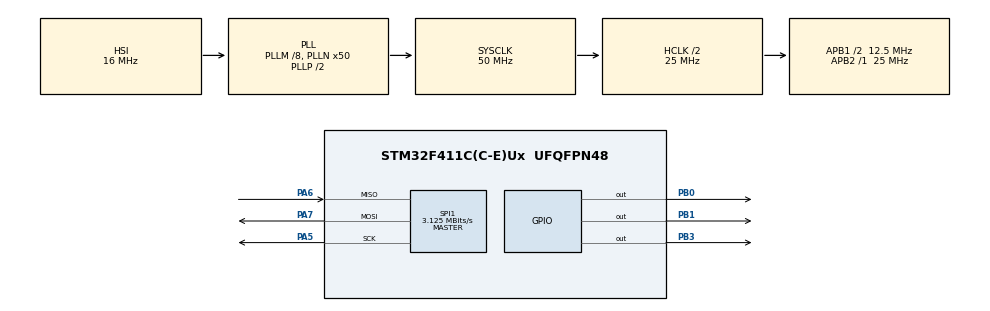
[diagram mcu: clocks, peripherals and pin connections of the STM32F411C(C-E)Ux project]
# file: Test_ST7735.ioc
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Mcu.Family=STM32F4
Mcu.Name=STM32F411C(C-E)Ux
Mcu.Package=UFQFPN48
NVIC.PriorityGroup=NVIC_PRIORITYGROUP_4
PA5.Mode=Full_Duplex_Master
PA5.Signal=SPI1_SCK
PA6.Mode=Full_Duplex_Master
PA6.Signal=SPI1_MISO
PA7.Mode=Full_Duplex_Master
PA7.Signal=SPI1_MOSI
PB0.Signal=GPIO_Output
PB1.Signal=GPIO_Output
PB3.Signal=GPIO_Output
PH0\ -\ OSC_IN.Mode=HSE-External-Oscillator
PH0\ -\ OSC_IN.Signal=RCC_OSC_IN
PH1\ -\ OSC_OUT.Mode=HSE-External-Oscillator
PH1\ -\ OSC_OUT.Signal=RCC_OSC_OUT
ProjectManager.HeapSize=0x200
ProjectManager.StackSize=0x400
ProjectManager.TargetToolchain=STM32CubeIDE
RCC.48MHZClocksFreq_Value=25000000
RCC.AHBCLKDivider=RCC_SYSCLK_DIV2
RCC.AHBFreq_Value=25000000
RCC.APB1CLKDivider=RCC_HCLK_DIV2
RCC.APB1Freq_Value=12500000
RCC.APB1TimFreq_Value=25000000
RCC.APB2Freq_Value=25000000
RCC.APB2TimFreq_Value=25000000
RCC.CortexFreq_Value=25000000
RCC.HCLKFreq_Value=25000000
RCC.HSE_VALUE=25000000
RCC.HSI_VALUE=16000000
RCC.LSE_VALUE=32768
RCC.PLLM=8
RCC.PLLN=50
RCC.SYSCLKFreq_VALUE=50000000
RCC.SYSCLKSource=RCC_SYSCLKSOURCE_PLLCLK
RCC.VCOOutputFreq_Value=100000000
SPI1.BaudRatePrescaler=SPI_BAUDRATEPRESCALER_8
SPI1.CalculateBaudRate=3.125 MBits/s
SPI1.Direction=SPI_DIRECTION_2LINES
SPI1.Mode=SPI_MODE_MASTER
SPI1.VirtualType=VM_MASTER
board=custom

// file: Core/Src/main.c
/* USER CODE BEGIN Header */
/**
  ******************************************************************************
  * @file           : main.c
  * @brief          : Main program body
  ******************************************************************************
  * @attention
  *
  * Copyright (c) 2023 STMicroelectronics.
  * All rights reserved.
  *
  * This software is licensed under terms that can be found in the LICENSE file
  * in the root directory of this software component.
  * If no LICENSE file comes with this software, it is provided AS-IS.
  *
  ******************************************************************************
  */
/* USER CODE END Header */
#include "main.h"
#include "stdio.h"

/* USER CODE BEGIN Includes */
#include "st7735.h"
#include "fonts.h"
/* USER CODE END Includes */

SPI_HandleTypeDef hspi1;

void SystemClock_Config(void);
static void MX_GPIO_Init(void);
static void MX_SPI1_Init(void);

int main(void)
{

  /* MCU Configuration--------------------------------------------------------*/

  /* Reset of all peripherals, Initializes the Flash interface and the Systick. */
  HAL_Init();

  /* Configure the system clock */
  SystemClock_Config();

  /* Initialize all configured peripherals */
  MX_GPIO_Init();
  MX_SPI1_Init();
  /* USER CODE BEGIN 2 */
  ST7735_Init();
  ST7735_FillScreen(ST7735_BLACK);
  int i =0;
  char str [64]= {0,};
  /* USER CODE END 2 */

  /* Infinite loop */
  while (1)
  {

    /* USER CODE BEGIN 3 */
	snprintf (str,23, "i = %d", i);
	ST7735_WriteString(10, 10, "Hello, World! Gus", Font_7x10, ST7735_RED, ST7735_BLACK);
	HAL_Delay(1000);
	i++;
	ST7735_WriteString(60, 60, str , Font_7x10, ST7735_RED, ST7735_BLACK);

  }
  /* USER CODE END 3 */
}

void SystemClock_Config(void)
{
  RCC_OscInitTypeDef RCC_OscInitStruct = {0};
  RCC_ClkInitTypeDef RCC_ClkInitStruct = {0};

  /** Configure the main internal regulator output voltage
  */
  __HAL_RCC_PWR_CLK_ENABLE();
  __HAL_PWR_VOLTAGESCALING_CONFIG(PWR_REGULATOR_VOLTAGE_SCALE1);

  /** Initializes the RCC Oscillators according to the specified parameters
  * in the RCC_OscInitTypeDef structure.
  */
  RCC_OscInitStruct.OscillatorType = RCC_OSCILLATORTYPE_HSI;
  RCC_OscInitStruct.HSIState = RCC_HSI_ON;
  RCC_OscInitStruct.HSICalibrationValue = RCC_HSICALIBRATION_DEFAULT;
  RCC_OscInitStruct.PLL.PLLState = RCC_PLL_ON;
  RCC_OscInitStruct.PLL.PLLSource = RCC_PLLSOURCE_HSI;
  RCC_OscInitStruct.PLL.PLLM = 8;
  RCC_OscInitStruct.PLL.PLLN = 50;
  RCC_OscInitStruct.PLL.PLLP = RCC_PLLP_DIV2;
  RCC_OscInitStruct.PLL.PLLQ = 4;
  if (HAL_RCC_OscConfig(&RCC_OscInitStruct) != HAL_OK)
  {
    Error_Handler();
  }

  /** Initializes the CPU, AHB and APB buses clocks
  */
  RCC_ClkInitStruct.ClockType = RCC_CLOCKTYPE_HCLK|RCC_CLOCKTYPE_SYSCLK
                              |RCC_CLOCKTYPE_PCLK1|RCC_CLOCKTYPE_PCLK2;
  RCC_ClkInitStruct.SYSCLKSource = RCC_SYSCLKSOURCE_PLLCLK;
  RCC_ClkInitStruct.AHBCLKDivider = RCC_SYSCLK_DIV2;
  RCC_ClkInitStruct.APB1CLKDivider = RCC_HCLK_DIV2;
  RCC_ClkInitStruct.APB2CLKDivider = RCC_HCLK_DIV1;

  if (HAL_RCC_ClockConfig(&RCC_ClkInitStruct, FLASH_LATENCY_0) != HAL_OK)
  {
    Error_Handler();
  }
}

static void MX_SPI1_Init(void)
{

  /* SPI1 parameter configuration*/
  hspi1.Instance = SPI1;
  hspi1.Init.Mode = SPI_MODE_MASTER;
  hspi1.Init.Direction = SPI_DIRECTION_2LINES;
  hspi1.Init.DataSize = SPI_DATASIZE_8BIT;
  hspi1.Init.CLKPolarity = SPI_POLARITY_LOW;
  hspi1.Init.CLKPhase = SPI_PHASE_1EDGE;
  hspi1.Init.NSS = SPI_NSS_SOFT;
  hspi1.Init.BaudRatePrescaler = SPI_BAUDRATEPRESCALER_8;
  hspi1.Init.FirstBit = SPI_FIRSTBIT_MSB;
  hspi1.Init.TIMode = SPI_TIMODE_DISABLE;
  hspi1.Init.CRCCalculation = SPI_CRCCALCULATION_DISABLE;
  hspi1.Init.CRCPolynomial = 10;
  if (HAL_SPI_Init(&hspi1) != HAL_OK)
  {
    Error_Handler();
  }

}

static void MX_GPIO_Init(void)
{
  GPIO_InitTypeDef GPIO_InitStruct = {0};

  /* GPIO Ports Clock Enable */
  __HAL_RCC_GPIOH_CLK_ENABLE();
  __HAL_RCC_GPIOA_CLK_ENABLE();
  __HAL_RCC_GPIOB_CLK_ENABLE();

  /*Configure GPIO pin Output Level */
  HAL_GPIO_WritePin(GPIOB, GPIO_PIN_0|GPIO_PIN_1|GPIO_PIN_3, GPIO_PIN_RESET);

  /*Configure GPIO pins : PB0 PB1 PB3 */
  GPIO_InitStruct.Pin = GPIO_PIN_0|GPIO_PIN_1|GPIO_PIN_3;
  GPIO_InitStruct.Mode = GPIO_MODE_OUTPUT_PP;
  GPIO_InitStruct.Pull = GPIO_NOPULL;
  GPIO_InitStruct.Speed = GPIO_SPEED_FREQ_LOW;
  HAL_GPIO_Init(GPIOB, &GPIO_InitStruct);

}

void Error_Handler(void)
{
  __disable_irq();
  while (1)
  {
  }
}
